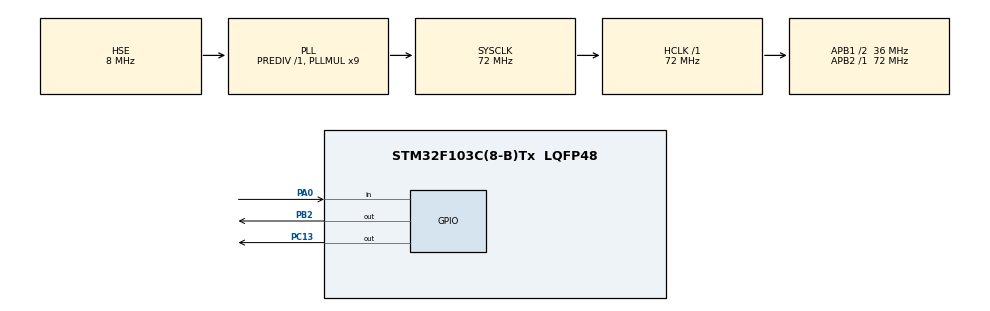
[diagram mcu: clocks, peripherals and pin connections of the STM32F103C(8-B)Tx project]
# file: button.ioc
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Mcu.Family=STM32F1
Mcu.Name=STM32F103C(8-B)Tx
Mcu.Package=LQFP48
NVIC.PriorityGroup=NVIC_PRIORITYGROUP_4
PA0-WKUP.GPIO_PuPd=GPIO_PULLUP
PA0-WKUP.Signal=GPIO_Input
PA13.Mode=Serial_Wire
PA13.Signal=SYS_JTMS-SWDIO
PA14.Mode=Serial_Wire
PA14.Signal=SYS_JTCK-SWCLK
PB2.Signal=GPIO_Output
PC13-TAMPER-RTC.Signal=GPIO_Output
PD0-OSC_IN.Mode=HSE-External-Oscillator
PD0-OSC_IN.Signal=RCC_OSC_IN
PD1-OSC_OUT.Mode=HSE-External-Oscillator
PD1-OSC_OUT.Signal=RCC_OSC_OUT
ProjectManager.HeapSize=0x200
ProjectManager.StackSize=0x400
ProjectManager.TargetToolchain=MDK-ARM V5.32
RCC.AHBFreq_Value=72000000
RCC.APB1CLKDivider=RCC_HCLK_DIV2
RCC.APB1Freq_Value=36000000
RCC.APB1TimFreq_Value=72000000
RCC.APB2Freq_Value=72000000
RCC.APB2TimFreq_Value=72000000
RCC.HCLKFreq_Value=72000000
RCC.PLLMUL=RCC_PLL_MUL9
RCC.PLLSourceVirtual=RCC_PLLSOURCE_HSE
RCC.SYSCLKFreq_VALUE=72000000
RCC.SYSCLKSource=RCC_SYSCLKSOURCE_PLLCLK
RCC.USBFreq_Value=72000000
board=custom

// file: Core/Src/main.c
/* USER CODE BEGIN Header */
/**
  ******************************************************************************
  * @file           : main.c
  * @brief          : Main program body
  ******************************************************************************
  * @attention
  *
  * Copyright (c) 2024 STMicroelectronics.
  * All rights reserved.
  *
  * This software is licensed under terms that can be found in the LICENSE file
  * in the root directory of this software component.
  * If no LICENSE file comes with this software, it is provided AS-IS.
  *
  ******************************************************************************
  */
/* USER CODE END Header */
#include "main.h"

/* USER CODE BEGIN Includes */
#include "button.h"
/* USER CODE END Includes */

void SystemClock_Config(void);
static void MX_GPIO_Init(void);

/* USER CODE BEGIN 0 */

/*--------------var led--------------*/
typedef enum{
	LED_OFF,
	LED1_BLINK_1HZ,
	LED2_BLINK_5HZ,
}Led_Status;

Led_Status led_status;

/*--------------bnt function--------------*/
Button_Typdef button1;
Button_Typdef button2;
void btn_pressing_callback(Button_Typdef *buttonx){
	// nhan button
	if(buttonx != &button1){
		switch(led_status){
			case LED_OFF:
				led_status = LED1_BLINK_1HZ;
				return;
			case LED1_BLINK_1HZ:
				led_status = LED2_BLINK_5HZ;
				return;
			case LED2_BLINK_5HZ:
				led_status = LED_OFF;
				return;
		}
	}else{
		switch(led_status){
			case LED_OFF:
				led_status = LED1_BLINK_1HZ;
				return;
			case LED1_BLINK_1HZ:
				led_status = LED2_BLINK_5HZ;
				return;
			case LED2_BLINK_5HZ:
				led_status = LED_OFF;
				return;
		}
	}
}

/*--------------led function--------------*/
void LED1_Blink1Hz(){
	static uint32_t tled1_blink;
	if(HAL_GetTick() - tled1_blink >= 500){
		tled1_blink = HAL_GetTick();
		HAL_GPIO_TogglePin(GPIOC,GPIO_PIN_13);
	}
}

void LED2_Blink5Hz(void){
	static uint32_t tled2_blink;
	if(HAL_GetTick() - tled2_blink >= 100){
		tled2_blink = HAL_GetTick();
		HAL_GPIO_TogglePin(GPIOC,GPIO_PIN_14);
	}
}

void LED_off(void){
	HAL_GPIO_WritePin(GPIOC,GPIO_PIN_13, 1);
	HAL_GPIO_WritePin(GPIOC,GPIO_PIN_14, 0);
}

void LED_handler(void){
	switch(led_status){
		case LED_OFF:
			LED1_Blink1Hz();
			return;
		case LED1_BLINK_1HZ:
			LED2_Blink5Hz();
			return;
		case LED2_BLINK_5HZ:
			LED_off();
			return;
	}
}

/* USER CODE END 0 */

int main(void)
{

  /* USER CODE BEGIN 1 */
	led_status = LED2_BLINK_5HZ;
	Button_Typdef btn1;
	Button_Typdef btn2;
  /* USER CODE END 1 */

  /* MCU Configuration--------------------------------------------------------*/

  /* Reset of all peripherals, Initializes the Flash interface and the Systick. */
  HAL_Init();

  /* Configure the system clock */
  SystemClock_Config();

  /* Initialize all configured peripherals */
  MX_GPIO_Init();
  /* USER CODE BEGIN 2 */
	Button_Init(&btn1,GPIOA,GPIO_PIN_0);
	Button_Init(&btn2,GPIOA,GPIO_PIN_1);

  /* USER CODE END 2 */

  /* Infinite loop */
  while (1)
  {
		button_handler(&btn1);
		button_handler(&btn2);
		LED_handler();
  }
}

void SystemClock_Config(void)
{
  RCC_OscInitTypeDef RCC_OscInitStruct = {0};
  RCC_ClkInitTypeDef RCC_ClkInitStruct = {0};

  /** Initializes the RCC Oscillators according to the specified parameters
  * in the RCC_OscInitTypeDef structure.
  */
  RCC_OscInitStruct.OscillatorType = RCC_OSCILLATORTYPE_HSE;
  RCC_OscInitStruct.HSEState = RCC_HSE_ON;
  RCC_OscInitStruct.HSEPredivValue = RCC_HSE_PREDIV_DIV1;
  RCC_OscInitStruct.HSIState = RCC_HSI_ON;
  RCC_OscInitStruct.PLL.PLLState = RCC_PLL_ON;
  RCC_OscInitStruct.PLL.PLLSource = RCC_PLLSOURCE_HSE;
  RCC_OscInitStruct.PLL.PLLMUL = RCC_PLL_MUL9;
  if (HAL_RCC_OscConfig(&RCC_OscInitStruct) != HAL_OK)
  {
    Error_Handler();
  }

  /** Initializes the CPU, AHB and APB buses clocks
  */
  RCC_ClkInitStruct.ClockType = RCC_CLOCKTYPE_HCLK|RCC_CLOCKTYPE_SYSCLK
                              |RCC_CLOCKTYPE_PCLK1|RCC_CLOCKTYPE_PCLK2;
  RCC_ClkInitStruct.SYSCLKSource = RCC_SYSCLKSOURCE_PLLCLK;
  RCC_ClkInitStruct.AHBCLKDivider = RCC_SYSCLK_DIV1;
  RCC_ClkInitStruct.APB1CLKDivider = RCC_HCLK_DIV2;
  RCC_ClkInitStruct.APB2CLKDivider = RCC_HCLK_DIV1;

  if (HAL_RCC_ClockConfig(&RCC_ClkInitStruct, FLASH_LATENCY_2) != HAL_OK)
  {
    Error_Handler();
  }
}

static void MX_GPIO_Init(void)
{
  GPIO_InitTypeDef GPIO_InitStruct = {0};

  /* GPIO Ports Clock Enable */
  __HAL_RCC_GPIOC_CLK_ENABLE();
  __HAL_RCC_GPIOD_CLK_ENABLE();
  __HAL_RCC_GPIOA_CLK_ENABLE();
  __HAL_RCC_GPIOB_CLK_ENABLE();

  /*Configure GPIO pin Output Level */
  HAL_GPIO_WritePin(GPIOC, GPIO_PIN_13, GPIO_PIN_RESET);

  /*Configure GPIO pin Output Level */
  HAL_GPIO_WritePin(GPIOB, GPIO_PIN_2, GPIO_PIN_RESET);

  /*Configure GPIO pin : PC13 */
  GPIO_InitStruct.Pin = GPIO_PIN_13;
  GPIO_InitStruct.Mode = GPIO_MODE_OUTPUT_PP;
  GPIO_InitStruct.Pull = GPIO_NOPULL;
  GPIO_InitStruct.Speed = GPIO_SPEED_FREQ_LOW;
  HAL_GPIO_Init(GPIOC, &GPIO_InitStruct);

  /*Configure GPIO pin : PA0 */
  GPIO_InitStruct.Pin = GPIO_PIN_0;
  GPIO_InitStruct.Mode = GPIO_MODE_INPUT;
  GPIO_InitStruct.Pull = GPIO_PULLUP;
  HAL_GPIO_Init(GPIOA, &GPIO_InitStruct);

  /*Configure GPIO pin : PB2 */
  GPIO_InitStruct.Pin = GPIO_PIN_2;
  GPIO_InitStruct.Mode = GPIO_MODE_OUTPUT_PP;
  GPIO_InitStruct.Pull = GPIO_NOPULL;
  GPIO_InitStruct.Speed = GPIO_SPEED_FREQ_LOW;
  HAL_GPIO_Init(GPIOB, &GPIO_InitStruct);

}

void Error_Handler(void)
{
  __disable_irq();
  while (1)
  {
  }
}
